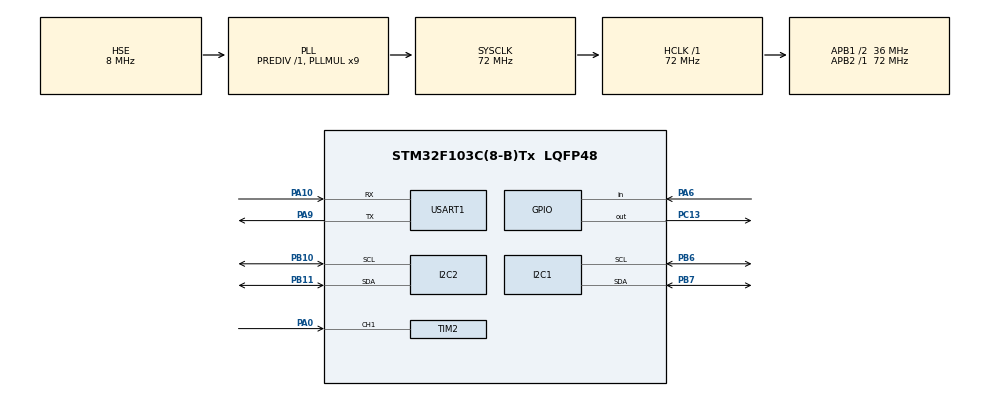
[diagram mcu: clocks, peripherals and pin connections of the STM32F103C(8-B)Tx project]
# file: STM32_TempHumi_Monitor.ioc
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Mcu.Family=STM32F1
Mcu.Name=STM32F103C(8-B)Tx
Mcu.Package=LQFP48
NVIC.PriorityGroup=NVIC_PRIORITYGROUP_4
PA10.Mode=Asynchronous
PA10.Signal=USART1_RX
PA13.Mode=Serial_Wire
PA13.Signal=SYS_JTMS-SWDIO
PA14.Mode=Serial_Wire
PA14.Signal=SYS_JTCK-SWCLK
PA0.Signal=S_TIM2_CH1_ETR
PA6.GPIO_PuPd=GPIO_PULLUP
PA6.Signal=GPIO_Input
PA9.Mode=Asynchronous
PA9.Signal=USART1_TX
PB10.Mode=I2C
PB10.Signal=I2C2_SCL
PB11.Mode=I2C
PB11.Signal=I2C2_SDA
PB6.Mode=I2C
PB6.Signal=I2C1_SCL
PB7.Mode=I2C
PB7.Signal=I2C1_SDA
PC13-TAMPER-RTC.PinState=GPIO_PIN_SET
PC13-TAMPER-RTC.Signal=GPIO_Output
PD0-OSC_IN.Mode=HSE-External-Oscillator
PD0-OSC_IN.Signal=RCC_OSC_IN
PD1-OSC_OUT.Mode=HSE-External-Oscillator
PD1-OSC_OUT.Signal=RCC_OSC_OUT
ProjectManager.HeapSize=0x200
ProjectManager.StackSize=0x400
ProjectManager.TargetToolchain=STM32CubeIDE
RCC.AHBFreq_Value=72000000
RCC.APB1CLKDivider=RCC_HCLK_DIV2
RCC.APB1Freq_Value=36000000
RCC.APB1TimFreq_Value=72000000
RCC.APB2Freq_Value=72000000
RCC.APB2TimFreq_Value=72000000
RCC.HCLKFreq_Value=72000000
RCC.PLLMUL=RCC_PLL_MUL9
RCC.PLLSourceVirtual=RCC_PLLSOURCE_HSE
RCC.SYSCLKFreq_VALUE=72000000
RCC.SYSCLKSource=RCC_SYSCLKSOURCE_PLLCLK
RCC.USBFreq_Value=72000000
SH.S_TIM2_CH1_ETR.0=TIM2_CH1,Input_Capture1_from_TI1
TIM2.Channel-Input_Capture1_from_TI1=TIM_CHANNEL_1
USART1.VirtualMode=VM_ASYNC
VP_TIM2_VS_ClockSourceINT.Mode=Internal
board=custom

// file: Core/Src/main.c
/* USER CODE BEGIN Header */
/**
  ******************************************************************************
  * @file           : main.c
  * @brief          : Main program body
  ******************************************************************************
  * @attention
  *
  * Copyright (c) 2026 STMicroelectronics.
  * All rights reserved.
  *
  * This software is licensed under terms that can be found in the LICENSE file
  * in the root directory of this software component.
  * If no LICENSE file comes with this software, it is provided AS-IS.
  *
  ******************************************************************************
  */
/* USER CODE END Header */
#include "main.h"

/* USER CODE BEGIN Includes */
#include "app_uart_command.h"
#include "app_th_meter.h"

/* USER CODE END Includes */

I2C_HandleTypeDef hi2c1;
I2C_HandleTypeDef hi2c2;

TIM_HandleTypeDef htim2;

UART_HandleTypeDef huart1;

void SystemClock_Config(void);
static void MX_GPIO_Init(void);
static void MX_I2C1_Init(void);
static void MX_I2C2_Init(void);
static void MX_TIM2_Init(void);
static void MX_USART1_UART_Init(void);

int main(void)
{

  /* MCU Configuration--------------------------------------------------------*/

  /* Reset of all peripherals, Initializes the Flash interface and the Systick. */
  HAL_Init();

  /* Configure the system clock */
  SystemClock_Config();

  /* Initialize all configured peripherals */
  MX_GPIO_Init();
  MX_I2C1_Init();
  MX_I2C2_Init();
  MX_TIM2_Init();
  MX_USART1_UART_Init();
  /* USER CODE BEGIN 2 */
  /* A SIM build must explicitly define APP_ENABLE_SIMULATION_SOURCE=1. */
#if defined(APP_ENABLE_SIMULATION_SOURCE) && (APP_ENABLE_SIMULATION_SOURCE != 0)
  (void)app_th_meter_select_source(APP_MEASUREMENT_SOURCE_SIMULATION);
#endif
  /* 业务初始化统一收口到应用层，main.c 只保留最小调度。 */
  app_th_meter_init();
  app_uart_command_init(&huart1);
  /* USER CODE END 2 */

  /* Infinite loop */
  while (1)
  {

    /* USER CODE BEGIN 3 */
    /* 所有周期任务都由 app_th_meter 在内部按节拍调度。 */
    app_th_meter_loop();
    app_uart_command_loop();
  /* USER CODE END 3 */
  }
}

void SystemClock_Config(void)
{
  RCC_OscInitTypeDef RCC_OscInitStruct = {0};
  RCC_ClkInitTypeDef RCC_ClkInitStruct = {0};

  /** Initializes the RCC Oscillators according to the specified parameters
  * in the RCC_OscInitTypeDef structure.
  */
  RCC_OscInitStruct.OscillatorType = RCC_OSCILLATORTYPE_HSE;
  RCC_OscInitStruct.HSEState = RCC_HSE_ON;
  RCC_OscInitStruct.HSEPredivValue = RCC_HSE_PREDIV_DIV1;
  RCC_OscInitStruct.HSIState = RCC_HSI_ON;
  RCC_OscInitStruct.PLL.PLLState = RCC_PLL_ON;
  RCC_OscInitStruct.PLL.PLLSource = RCC_PLLSOURCE_HSE;
  RCC_OscInitStruct.PLL.PLLMUL = RCC_PLL_MUL9;
  if (HAL_RCC_OscConfig(&RCC_OscInitStruct) != HAL_OK)
  {
    Error_Handler();
  }

  /** Initializes the CPU, AHB and APB buses clocks
  */
  RCC_ClkInitStruct.ClockType = RCC_CLOCKTYPE_HCLK|RCC_CLOCKTYPE_SYSCLK
                              |RCC_CLOCKTYPE_PCLK1|RCC_CLOCKTYPE_PCLK2;
  RCC_ClkInitStruct.SYSCLKSource = RCC_SYSCLKSOURCE_PLLCLK;
  RCC_ClkInitStruct.AHBCLKDivider = RCC_SYSCLK_DIV1;
  RCC_ClkInitStruct.APB1CLKDivider = RCC_HCLK_DIV2;
  RCC_ClkInitStruct.APB2CLKDivider = RCC_HCLK_DIV1;

  if (HAL_RCC_ClockConfig(&RCC_ClkInitStruct, FLASH_LATENCY_2) != HAL_OK)
  {
    Error_Handler();
  }
}

static void MX_I2C1_Init(void)
{

  hi2c1.Instance = I2C1;
  hi2c1.Init.ClockSpeed = 100000;
  hi2c1.Init.DutyCycle = I2C_DUTYCYCLE_2;
  hi2c1.Init.OwnAddress1 = 0;
  hi2c1.Init.AddressingMode = I2C_ADDRESSINGMODE_7BIT;
  hi2c1.Init.DualAddressMode = I2C_DUALADDRESS_DISABLE;
  hi2c1.Init.OwnAddress2 = 0;
  hi2c1.Init.GeneralCallMode = I2C_GENERALCALL_DISABLE;
  hi2c1.Init.NoStretchMode = I2C_NOSTRETCH_DISABLE;
  if (HAL_I2C_Init(&hi2c1) != HAL_OK)
  {
    Error_Handler();
  }

}

static void MX_I2C2_Init(void)
{

  hi2c2.Instance = I2C2;
  hi2c2.Init.ClockSpeed = 100000;
  hi2c2.Init.DutyCycle = I2C_DUTYCYCLE_2;
  hi2c2.Init.OwnAddress1 = 0;
  hi2c2.Init.AddressingMode = I2C_ADDRESSINGMODE_7BIT;
  hi2c2.Init.DualAddressMode = I2C_DUALADDRESS_DISABLE;
  hi2c2.Init.OwnAddress2 = 0;
  hi2c2.Init.GeneralCallMode = I2C_GENERALCALL_DISABLE;
  hi2c2.Init.NoStretchMode = I2C_NOSTRETCH_DISABLE;
  if (HAL_I2C_Init(&hi2c2) != HAL_OK)
  {
    Error_Handler();
  }

}

static void MX_TIM2_Init(void)
{

  TIM_ClockConfigTypeDef sClockSourceConfig = {0};
  TIM_MasterConfigTypeDef sMasterConfig = {0};
  TIM_IC_InitTypeDef sConfigIC = {0};

  htim2.Instance = TIM2;
  htim2.Init.Prescaler = 0;
  htim2.Init.CounterMode = TIM_COUNTERMODE_UP;
  htim2.Init.Period = 65535;
  htim2.Init.ClockDivision = TIM_CLOCKDIVISION_DIV1;
  htim2.Init.AutoReloadPreload = TIM_AUTORELOAD_PRELOAD_DISABLE;
  if (HAL_TIM_Base_Init(&htim2) != HAL_OK)
  {
    Error_Handler();
  }
  sClockSourceConfig.ClockSource = TIM_CLOCKSOURCE_INTERNAL;
  if (HAL_TIM_ConfigClockSource(&htim2, &sClockSourceConfig) != HAL_OK)
  {
    Error_Handler();
  }
  if (HAL_TIM_IC_Init(&htim2) != HAL_OK)
  {
    Error_Handler();
  }
  sMasterConfig.MasterOutputTrigger = TIM_TRGO_RESET;
  sMasterConfig.MasterSlaveMode = TIM_MASTERSLAVEMODE_DISABLE;
  if (HAL_TIMEx_MasterConfigSynchronization(&htim2, &sMasterConfig) != HAL_OK)
  {
    Error_Handler();
  }
  sConfigIC.ICPolarity = TIM_INPUTCHANNELPOLARITY_RISING;
  sConfigIC.ICSelection = TIM_ICSELECTION_DIRECTTI;
  sConfigIC.ICPrescaler = TIM_ICPSC_DIV1;
  sConfigIC.ICFilter = 0;
  if (HAL_TIM_IC_ConfigChannel(&htim2, &sConfigIC, TIM_CHANNEL_1) != HAL_OK)
  {
    Error_Handler();
  }

}

static void MX_USART1_UART_Init(void)
{

  huart1.Instance = USART1;
  huart1.Init.BaudRate = 115200;
  huart1.Init.WordLength = UART_WORDLENGTH_8B;
  huart1.Init.StopBits = UART_STOPBITS_1;
  huart1.Init.Parity = UART_PARITY_NONE;
  huart1.Init.Mode = UART_MODE_TX_RX;
  huart1.Init.HwFlowCtl = UART_HWCONTROL_NONE;
  huart1.Init.OverSampling = UART_OVERSAMPLING_16;
  if (HAL_UART_Init(&huart1) != HAL_OK)
  {
    Error_Handler();
  }

}

static void MX_GPIO_Init(void)
{
  GPIO_InitTypeDef GPIO_InitStruct = {0};

  /* GPIO Ports Clock Enable */
  __HAL_RCC_GPIOC_CLK_ENABLE();
  __HAL_RCC_GPIOD_CLK_ENABLE();
  __HAL_RCC_GPIOA_CLK_ENABLE();
  __HAL_RCC_GPIOB_CLK_ENABLE();

  /*Configure GPIO pin Output Level */
  HAL_GPIO_WritePin(GPIOC, GPIO_PIN_13, GPIO_PIN_SET);

  /*Configure GPIO pin : PC13 */
  GPIO_InitStruct.Pin = GPIO_PIN_13;
  GPIO_InitStruct.Mode = GPIO_MODE_OUTPUT_PP;
  GPIO_InitStruct.Pull = GPIO_NOPULL;
  GPIO_InitStruct.Speed = GPIO_SPEED_FREQ_LOW;
  HAL_GPIO_Init(GPIOC, &GPIO_InitStruct);

  /*Configure GPIO pin : PA6 */
  GPIO_InitStruct.Pin = GPIO_PIN_6;
  GPIO_InitStruct.Mode = GPIO_MODE_INPUT;
  GPIO_InitStruct.Pull = GPIO_PULLUP;
  HAL_GPIO_Init(GPIOA, &GPIO_InitStruct);

}

void Error_Handler(void)
{
  __disable_irq();
  while (1)
  {
  }
}
